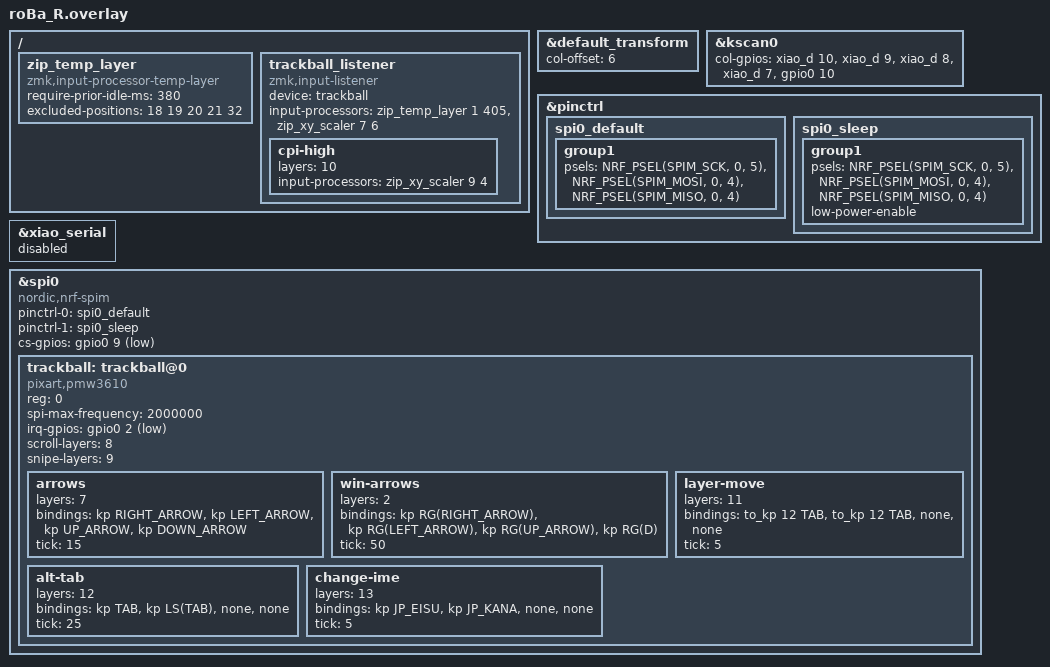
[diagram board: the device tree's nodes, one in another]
#include "roBa.dtsi"
#include <dt-bindings/zmk/keys.h>
#include <input/processors.dtsi>
#define JP_KANA         LANGUAGE_1        // かな
#define JP_EISU         LANGUAGE_2        // 英数

&default_transform {
    col-offset = <6>;
};

&kscan0 {
        col-gpios
            = <&xiao_d 10 GPIO_ACTIVE_HIGH>
            , <&xiao_d 9 GPIO_ACTIVE_HIGH> 
            , <&xiao_d 8 GPIO_ACTIVE_HIGH> 
            , <&xiao_d 7 GPIO_ACTIVE_HIGH> 
            , <&gpio0 10 GPIO_ACTIVE_HIGH>
            ;
};

&pinctrl {
    spi0_default: spi0_default {
        group1 {
            psels = <NRF_PSEL(SPIM_SCK, 0, 5)>,
                <NRF_PSEL(SPIM_MOSI, 0, 4)>,
                <NRF_PSEL(SPIM_MISO, 0, 4)>;
        };
    };

    spi0_sleep: spi0_sleep {
        group1 {
            psels = <NRF_PSEL(SPIM_SCK, 0, 5)>,
                <NRF_PSEL(SPIM_MOSI, 0, 4)>,
                <NRF_PSEL(SPIM_MISO, 0, 4)>;
            low-power-enable;
        };
    };
};

&xiao_serial { status = "disabled"; };

&spi0 {
    status = "okay";
    compatible = "nordic,nrf-spim";
    pinctrl-0 = <&spi0_default>;
    pinctrl-1 = <&spi0_sleep>;
    pinctrl-names = "default", "sleep";
    cs-gpios = <&gpio0 9 GPIO_ACTIVE_LOW>;

    trackball: trackball@0 {
        status = "okay";
        compatible = "pixart,pmw3610";
        reg = <0>;
        spi-max-frequency = <2000000>;
        irq-gpios = <&gpio0 2 (GPIO_ACTIVE_LOW | GPIO_PULL_UP)>;
       scroll-layers = <8>;
       snipe-layers = <9>;

arrows {
            layers = <7>;
            bindings =
                <&kp RIGHT_ARROW>,
                <&kp LEFT_ARROW>,
                <&kp UP_ARROW>,
                <&kp DOWN_ARROW>;

            /*   optional: ball action configuration  */
            tick = <15>;
            // wait-ms = <5>;
            // tap-ms = <5>;
        };

win-arrows {
            layers = <2>;
            bindings =
                <&kp RG(RIGHT_ARROW)>,
                <&kp RG(LEFT_ARROW)>,
                <&kp RG(UP_ARROW)>,
                <&kp RG(D)>;

            /*   optional: ball action configuration  */
            tick = <50>;
            // wait-ms = <5>;
            // tap-ms = <5>;
        };

layer-move {
            layers = <11>;
            bindings =
                <&to_kp 12 TAB>,
                <&to_kp 12 TAB>,
                <&none>,
                <&none>;

            /*   optional: ball action configuration  */
            tick = <5>;
            // wait-ms = <5>;
            // tap-ms = <5>;
        };

alt-tab {
            layers = <12>;
            bindings =
                <&kp TAB>,
                <&kp LS(TAB)>,
                <&none>,
                <&none>;

            /*   optional: ball action configuration  */
            tick = <25>;
            // wait-ms = <5>;
            // tap-ms = <5>;
        };

change-ime {
            layers = <13>;
            bindings =
                <&kp JP_EISU>,
                <&kp JP_KANA>,
                <&none>,
                <&none>;

            /*   optional: ball action configuration  */
            tick = <5>;
            // wait-ms = <5>;
            // tap-ms = <5>;
        };
    };
};

/ {
    /omit-if-no-ref/ zip_temp_layer: zip_temp_layer {
        compatible = "zmk,input-processor-temp-layer";
        #input-processor-cells = <2>;
        require-prior-idle-ms = <380>;
        excluded-positions = <
            18 //
            19 //
            20 //
            21 //
            32 //
        >;
    };

    trackball_listener {
        compatible = "zmk,input-listener";
        device = <&trackball>;
        input-processors =
                <&zip_temp_layer 1 405>,
                <&zip_xy_scaler 7 6>;

        cpi-high {
            layers = <10>;
            input-processors = <&zip_xy_scaler 9 4>;
        };
    };
};
